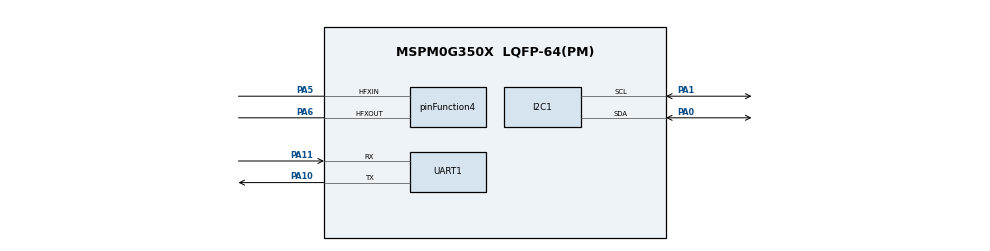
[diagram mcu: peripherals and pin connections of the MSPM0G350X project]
/**
 *
 * @cliArgs --device "MSPM0G350X" --part "Default" --package "LQFP-64(PM)" --product "mspm0_sdk@2.08.00.03"
 * @versions {"tool":"1.28.0+4712"}
 */

/**
 * Import the modules used in this configuration.
 */
const I2C     = scripting.addModule("/ti/driverlib/I2C", {}, false);
const I2C1    = I2C.addInstance();
const SYSCTL  = scripting.addModule("/ti/driverlib/SYSCTL");
const SYSTICK = scripting.addModule("/ti/driverlib/SYSTICK");
const UART    = scripting.addModule("/ti/driverlib/UART", {}, false);
const UART1   = UART.addInstance();

/**
 * Write custom configuration values to the imported modules.
 */
const divider7       = system.clockTree["PLL_PDIV"];
divider7.divideValue = 2;

const divider9       = system.clockTree["UDIV"];
divider9.divideValue = 2;

const multiplier2         = system.clockTree["PLL_QDIV"];
multiplier2.multiplyValue = 4;

const mux4       = system.clockTree["EXHFMUX"];
mux4.inputSelect = "EXHFMUX_XTAL";

const mux8       = system.clockTree["HSCLKMUX"];
mux8.inputSelect = "HSCLKMUX_SYSPLL2X";

const mux10       = system.clockTree["MFPCLKMUX"];
mux10.inputSelect = "MFPCLKMUX_HFCLK";

const mux12       = system.clockTree["SYSPLLMUX"];
mux12.inputSelect = "zSYSPLLMUX_HFCLK";

const pinFunction4                        = system.clockTree["HFXT"];
pinFunction4.enable                       = true;
pinFunction4.inputFreq                    = 40;
pinFunction4.HFCLKMonitor                 = true;
pinFunction4.HFXTStartup                  = 10;
pinFunction4.peripheral.$assign           = "SYSCTL";
pinFunction4.peripheral.hfxInPin.$assign  = "PA5";
pinFunction4.peripheral.hfxOutPin.$assign = "PA6";

I2C1.$name                           = "I2C_0";
I2C1.basicEnableController           = true;
I2C1.basicControllerStandardBusSpeed = "Fast";
I2C1.peripheral.sdaPin.$assign       = "PA0";
I2C1.peripheral.sclPin.$assign       = "PA1";
I2C1.sdaPinConfig.$name              = "ti_driverlib_gpio_GPIOPinGeneric2";
I2C1.sclPinConfig.$name              = "ti_driverlib_gpio_GPIOPinGeneric3";

const Board = scripting.addModule("/ti/driverlib/Board", {}, false);

SYSCTL.forceDefaultClkConfig = true;
SYSCTL.clockTreeEn           = true;

SYSTICK.periodEnable  = true;
SYSTICK.period        = 400000;
SYSTICK.systickEnable = true;

UART1.$name                            = "UART_PC";
UART1.targetBaudRate                   = 2000000;
UART1.peripheral.$assign               = "UART0";
UART1.peripheral.rxPin.$assign         = "PA11";
UART1.peripheral.txPin.$assign         = "PA10";
UART1.txPinConfig.direction            = scripting.forceWrite("OUTPUT");
UART1.txPinConfig.hideOutputInversion  = scripting.forceWrite(false);
UART1.txPinConfig.onlyInternalResistor = scripting.forceWrite(false);
UART1.txPinConfig.passedPeripheralType = scripting.forceWrite("Digital");
UART1.txPinConfig.$name                = "ti_driverlib_gpio_GPIOPinGeneric0";
UART1.rxPinConfig.hideOutputInversion  = scripting.forceWrite(false);
UART1.rxPinConfig.onlyInternalResistor = scripting.forceWrite(false);
UART1.rxPinConfig.passedPeripheralType = scripting.forceWrite("Digital");
UART1.rxPinConfig.$name                = "ti_driverlib_gpio_GPIOPinGeneric1";

/**
 * Pinmux solution for unlocked pins/peripherals. This ensures that minor changes to the automatic solver in a future
 * version of the tool will not impact the pinmux you originally saw.  These lines can be completely deleted in order to
 * re-solve from scratch.
 */
I2C1.peripheral.$suggestSolution           = "I2C0";
Board.peripheral.$suggestSolution          = "DEBUGSS";
Board.peripheral.swclkPin.$suggestSolution = "PA20";
Board.peripheral.swdioPin.$suggestSolution = "PA19";
